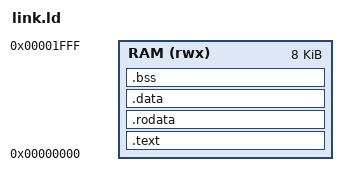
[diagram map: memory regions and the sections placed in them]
OUTPUT_ARCH("riscv")
ENTRY(_start)

MEMORY
{
    RAM (rwx) : ORIGIN = 0x00000000, LENGTH = 8K
}

SECTIONS
{
    .text : {
        . = ALIGN(4);
        *(.init)
        *(.text .text.*)
        . = ALIGN(4);
        _etext = .;
    } > RAM

    .rodata : {
        . = ALIGN(4);
        *(.rodata .rodata.*)
        *(.srodata .srodata.*)
        . = ALIGN(4);
    } > RAM

    .data : {
        . = ALIGN(4);
        *(.data .data.*)
        *(.sdata .sdata.*)
        . = ALIGN(4);
        _edata = .;
    } > RAM

    .bss : {
        . = ALIGN(4);
        _bss_start = .;
        *(.bss .bss.*)
        *(.sbss .sbss.*)
        *(COMMON)
        . = ALIGN(4);
        _bss_end = .;
    } > RAM

    . = ALIGN(16);
    _stack_bottom = .;
    . = ORIGIN(RAM) + LENGTH(RAM) - 16;
    _stack_top = .;
}
